# MCAN_CFG_52608000h register map
Vendor: Texas Instruments
Peripheral module from a debugger description file (folder AM263P).
Registers are 32-bit, read-write, reset 0x0 unless marked. A register's access mark holds for its fields unless they carry their own. Offsets are as the file gives them; lines under a group give offsets from that group; [hi:lo] are bit positions; {n}, {i} and the like mark numbered series; 'fields as' and 'values as' point back to an identical list; <NAME> marks a mode.

## CFG
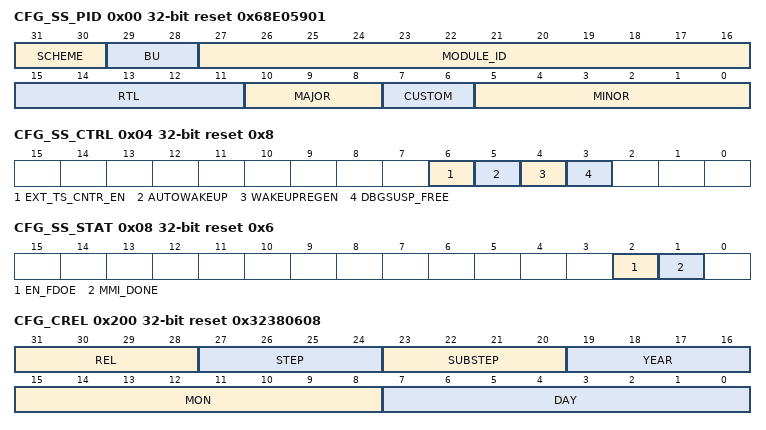
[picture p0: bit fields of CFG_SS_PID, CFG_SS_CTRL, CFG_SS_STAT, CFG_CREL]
0x00 CFG_SS_PID ro reset 0x68E05901 — Revision Register. The Revision Register contains the major and minor revisions for the MCANSS.
  [31:30] SCHEME — PID register scheme
  [29:28] BU — Business Unit: 10 = Processors
  [27:16] MODULE_ID
  [15:11] RTL — RTL revision. Will vary depending on release.
  [10:8] MAJOR — Major revision
  [7:6] CUSTOM
  [5:0] MINOR — Minor revision
0x04 CFG_SS_CTRL reset 0x8 — Control Register. The Control Register contains general control bits for the MCANSS.
  [6] EXT_TS_CNTR_EN — External TimeStamp Counter Enable
  [5] AUTOWAKEUP — Automatic Wakeup Enable
  [4] WAKEUPREGEN — Wakeup Request Enable
  [3] DBGSUSP_FREE — 0-Honor Debug Suspend, 1-Disregard debug suspend
0x08 CFG_SS_STAT ro reset 0x6 — Status Register. The Status Register provides general status bits for the MCANSS.
  [2] EN_FDOE — Enable FD configuration. Reflects the value of mcanss_enable_fdoe configuration port
  [1] MMI_DONE — 0:Memory Initialization is in progress, 1:Memory Intialization Done
0x0C CFG_SS_ICS wo — Interrupt Clear Shadow Register. Write 1 to clear interrupt bits.
  [0] ICS — This bit contains the External TimeStamp Counter Overflow Interrupt status. Write '1' to clear bits. [ICS - Interrupt Clear Shadow Register]
0x10 CFG_SS_IRS ro — Interrupt Raw Status Register. Write 1 to set interrupt bits.
  [0] IRS — External TimeStamp Counter Overflow Interrupt status. Read raw interrupt status. [IRS - Interrupt Raw Status Register]
0x14 CFG_SS_IECS wo — Interrupt Enable Clear Shadow Register. Write 1 to clear interrupt enable bits.
  [0] IECS — External TimeStamp Counter Overflow Interrupt. Write '1' to clear bits. [IECS - Interrupt Enable Clear Shadow Register]
0x18 CFG_SS_IE — Interrupt Enable Register. Write 1 to set interrupt bits.
  [0] IE — External TimeStamp Counter Overflow Interrupt. Write '1' to set interrupt enable. Read returns interrupt enable. [IE - Interrupt Enable Register]
0x1C CFG_SS_IES ro — Interrupt Enable Status Register. Read enabled interrupts.
  [0] IES — External TimeStamp Counter Overflow Interrupt. Read Enabled Interrupts. [IES - Interrupt Enable Status]
0x20 CFG_SS_EOI wo — End Of Interrupt (EOI) Register. The EOI register is used to re-trigger the pulse interrupt signal to ensure that any nested interrupt events are serviced. For level interrupt signals the EOI register is not functional and must not be used.
  [7:0] EOI — Write with bit position of targeted interrupt. [E.g. Ext TS is bit 0].Upon write, level interrupt will clear and if unserviced interrupt counter > 1 will issue another pulse interrupt. Field values: 8'h00: EOI value for External TS interrupt 8'h01: EOI value for mcan[0] interrupt 8'h02: EOI value for mcan[1] interruptAll other values are not applicable[EOI - End Of Interrupt]
0x24 CFG_SS_EXT_TS_PS — External Timestamp Prescaler Register.
  [23:0] PRESCALE — External Timestamp Prescaler reload value.External Timestamp count rate is host clock rate divided by this valuewith one exception: a value of 0 has the same effect as 1 .
0x28 CFG_SS_EXT_TS_USIC ro — External Timestamp Unserviced Interrupts Counter Register.
  [4:0] EXT_TS_INTR_CNTR — Number of unserviced rollover interrupts. If >1 an EOI write will issue another pulse interrupt [EXT_TS_USIC - External TImeStamp Unserviced Interrupts Counter]
0x200 CFG_CREL ro reset 0x32380608 — Core Release Register. Release dependent constant (version + date).
  [31:28] REL — Core Release
  [27:24] STEP — Step of Core Release
  [23:20] SUBSTEP — Sub-Step of Core Release
  [19:16] YEAR — Time Stamp Year
  [15:8] MON — Time Stamp Month
  [7:0] DAY — Time Stamp Day
0x204 CFG_ENDN ro reset 0x87654321 — Endian Register. Constant 8765 4321h.
  [31:0] ETV — Endianess test value
0x208 CFG_CUST ro — Custom Register.
  [31:0] CUST — Custom
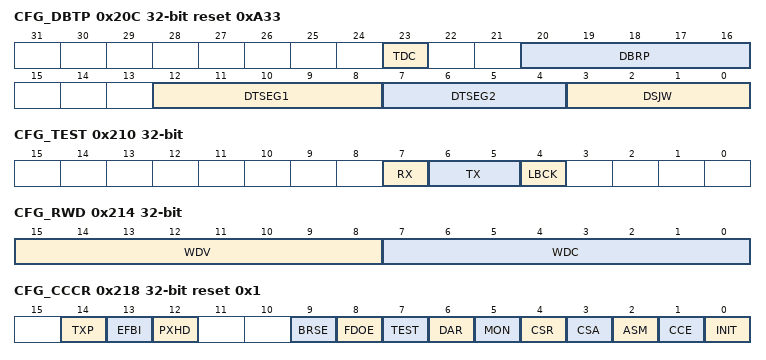
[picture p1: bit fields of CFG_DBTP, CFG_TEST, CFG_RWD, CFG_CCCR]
0x20C CFG_DBTP reset 0xA33 — Data Bit Timing & Prescaler Register. Configuration of data phase bit timing, transmitter delay compensation enable. This register is only writable if the MCAN_CCCR[1] CCE and MCAN_CCCR[0] INIT bits are set. The CAN bit time may be programed in the range of 4 to 49 time quanta. The CAN time quantum may be programmed in the range of 1 to 32 MCAN functional clock periods. tq = (MCAN_DBTP[20-16] DBRP + 1) mtq (minimum time quantum = CAN clock period (MCAN functional clock)). The MCAN_DBTP[12-8] DTSEG1 field is the sum of Prop_Seg and Phase_Seg1. The MCAN_DBTP[7-4] DTSEG2 field is Phase_Seg2. Therefore the length of the bit time is (programmed values) [MCAN_DBTP[12-8] DTSEG1 + MCAN_DBTP[7-4] DTSEG2 + 3] tq or (functional values) [Sync_Seg + Prop_Seg + Phase_Seg1 + Phase_Seg2] tq. The Information Processing Time (IPT) is zero, meaning the data for the next bit is available at the first clock edge after the sample point. Note: With a CAN clock (MCAN functional clock) of 8 MHz, the reset value of 0000 0A33h configures the MCAN module for a data phase bit rate of 500 kbit/s. Note: The bit rate configured for the CAN FD data phase via the MCAN_DBTP register must be higher or equal to the bit rate configured for the arbitration phase via the MCAN_DBTP register.
  [23] TDC — Transmitter Delay Compensation 1'b0 = Transmitter Delay Compensation disabled 1'b1 = Transmitter Delay Compensation enabled
  [20:16] DBRP — Data Baud Rate Prescaler The value by which the oscillator frequency is divided for generating the bit time quanta. The bit time is built up from a multiple of this quanta. The actual interpretation by the hardware of this value is such that one more than the value programmed here is used.
  [12:8] DTSEG1 — Data time segment before smaple point. The actual interpretation by the hardware of this value is such that one more than the value programmed here is used.
  [7:4] DTSEG2 — Data time segment after sample point. The actual interpretation by the hardware of this value is such that one more than the value programmed here is used.
  [3:0] DSJW — Data resynchronization Jump Width. The actual interpretation by the hardware of this value is such that one more than the value programmed here is used.
0x210 CFG_TEST access per field — Test Register. Test mode selection. Write access to the MCAN_TEST register has to be enabled by setting the MCAN_CCCR[7] TEST bit.
  [7] RX ro — Receive Pin Monitors the actual value of the MCAN RX pin 1'b0 = The CAN bus is dominant 1'b1 = The CAN bus is recessive
  [6:5] TX rw — Control of Transmit Pin 2'b00 = Reset value, the MCAN TX pin controlled by the CAN Core, updated at the end of the CAN bit time 2'b01 = Sample Point can be monitored at the MCAN TX pin 2'b10 = Dominant ('0') level at the MCAN TX pin 2'b11 = Recessive ('1') at the MCAN TX pin
  [4] LBCK rw — Loop Back Mode 1'b0 = Reset value, Loopback Mode is disabled 1'b1 = Loopback Mode is enabled(see Test Modes)
0x214 CFG_RWD access per field — RAM Watchdog. Monitors the READY output of the Message RAM.
  [15:8] WDV ro — Watchdog Value Actual Message RAM Watchdog Counter Value.
  [7:0] WDC rw — Watchdog Counter Value Start value of the Message RAM Watchdog Counter. With the reset value of 8'h0 the counter is disabled.
0x218 CFG_CCCR access per field reset 0x1 — CC Control Register. Operation mode configuration.
  [14] TXP rw — Transmit Pause If this bit is set, the MCAN module pauses for two CAN bit times before starting the next transmission after itself has successfully transmitted a frame(see Tx Handling) . 1'b0 = Transmit pause disabled 1'b1 = Transmit pause enabled
  [13] EFBI rw — Edge Filtering durign Bus Integration 1'b0 = Edge filtering disabled 1'b1 = Two consecutive dominant tq required to detect an edge for hard synchronization
  [12] PXHD rw — Protocol Exception Handling Disable 1'b0 = Protocol exception handling enabled 1'b1 = Protocol exception handling disabled Note: When protocol exception handling is disabled, the MCAN module will transmit an error frame when it detects a protocol exception condition.
  [9] BRSE rw — Bit Rate Switch Enable 1'b0 = Bit rate switching for transmissions disabled 1'b1 = Bit rate switching for transmissions enabled Note: When CAN FD operation is disabled the MCAN_CCCR[8] FDOE = 1'b0, the MCAN_CCCR[9] BRSE bit is not evaluated.
  [8] FDOE rw — FD Operation Enable 1'b0 = FD operation disabled 1'b1 = FD operation enabled
  [7] TEST rw — Test Mode enable 1'b0 = Normal operation. The MCAN_TEST register holds reset values. 1'b1 = Test Mode. Write access to the MCAN_TEST register enabled
  [6] DAR rw — Disable Automatic Regransmission 1'b0 = Automatic retransmission of messages not transmitted successfully enabled 1'b1 = Automatic retransmission disabled
  [5] MON rw — Bus Monitoring Mode The MCAN_CCCR[5] MON bit can only be set by the Host CPU when both MCAN_CCCR[1] CCE and MCAN_CCCR[0] INIT bits are set to 1. The bit can be reset by the Host CPU at any time. 1'b0 = Bus Monitoring Mode is disabled 1'b1 = Bus Monitoring Mode is enabled
  [4] CSR rw — Clock Stop Request 1'b0 = No clock stop is requested 1'b1 = Clock stop requested. When clock stop is requested, first the MCAN_CCCR[0] INIT bit and then the MCAN_CCCR[3] CSA bit will be set after all pending transfer requests have been completed and the CAN bus reached idle.
  [3] CSA ro — Clock Stop Acknowledge 1'b0 = No clock stop acknowledged 1'b1 = The MCAN module may be set in power down by stopping MCAN interface clock and MCAN functional clock
  [2] ASM rw — Restriced Operation Mode The MCAN_CCCR[2] ASM bit can only be set by the Host CPU when both MCAN_CCCR[1] CCE and MCAN_CCCR[0] INIT bits are set to 1. The bit can be reset by the Host CPU at any time. For a description of the Restricted Operation Mode, see Restricted Operation Mode. 1'b0 = Normal CAN operation 1'b1 = Restricted Operation Mode active
  [1] CCE rw — Configuration Change Enable 1'b0 = The Host CPU has no write access to the protected configuration registers 1'b1 = The Host CPU has write access to the protected configuration registers (while the MCAN_CCCR[0] INIT = 1)
  [0] INIT rw — Initialization 1'b0 = Normal Operation 1'b1 = Initialization is started Note: Due to the synchronization mechanism between the two clock domains, there may be a delay until the value written to the MCAN_CCCR[0] INIT bit can be read back. Therefore the software has to assure that the previous value written to the MCAN_CCCR[0] INIT bit has been accepted by Reading the MCAN_CCCR[0] INIT bit before setting the MCAN_CCCR[0] INIT bit to a new value.
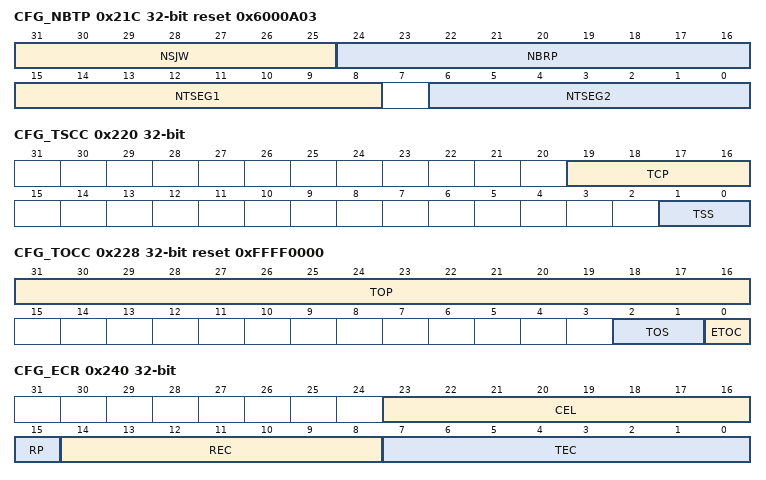
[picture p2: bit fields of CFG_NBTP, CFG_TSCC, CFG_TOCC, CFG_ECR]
0x21C CFG_NBTP reset 0x6000A03 — Nominal Bit Timing & Prescaler Register. Configuration of arbitration phase bit timing. This register is only writable if the MCAN_CCCR[1] CCE and MCAN_CCCR[0] INIT bits are set. The CAN bit time may be programed in the range of 4 to 385 time quanta. The CAN time quantum may be programmed in the range of 1 to 512 MCAN functional clock periods. tq = (MCAN_NBTP[24-16] NBRP + 1) mtq. The MCAN_NBTP[15-8] NTSEG1 field is the sum of Prop_Seg and Phase_Seg1. The MCAN_NBTP[6-0] NTSEG2 field is Phase_Seg2. Therefore the length of the bit time is (programmed values) [MCAN_NBTP[15-8] NTSEG1 + MCAN_NBTP[6-0] NTSEG2 + 3] tq or (functional values) [Sync_Seg + Prop_Seg + Phase_Seg1 + Phase_Seg2] tq. The Information Processing Time (IPT) is zero, meaning the data for the next bit is available at the first clock edge after the sample point.
  [31:25] NSJW — Nominal Resynchronization Jump Width
  [24:16] NBRP — Nominal Baud Rate Prescaler
  [15:8] NTSEG1 — Nominal Time segment before sample point
  [6:0] NTSEG2 — Nominal Time segment after sample point
0x220 CFG_TSCC — Timestamp Counter Configuration. Timestamp counter prescaler setting, selection of internal/external timestamp vector.
  [19:16] TCP — Timestamp Counter Prescaler Configures the timestamp and timeout counters time unit in multiples of CAN bit times [1-16]. The actual interpretation by the hardware of this value is such that one more than the value programmed here is used. Note: With CAN FD an external counter is required for timestamp generation. MCAN_TSCC[1-0] TSS = 2'b10
  [1:0] TSS — Timestamp Select 2'b00 = Timestamp counter value always 0 2'b01 = Timestamp counter value incremented according to the MCAN_TSCC[19-16] TCP field 2'b10 = External timestamp counter value used 2'b11 = Same as 2'b00
0x224 CFG_TSCV — Timestamp Counter Value.
  [15:0] TSC — Timestamp Counter The internal/external Timestamp Counter value is captured on start of frame (both Rx and Tx). When the MCAN_TSCC[1-0] TSS = 2'b01, the Timestamp Counter is incremented in multiples of CAN bit times [1-16] depending on the configuration of the MCAN_TSCC[19-16] TCP field. A wrap around sets interrupt flag MCAN_IR[16] TSW. Write access resets the counter to zero. When the MCAN_TSCC[1-0] TSS = 2'b10, the MCAN_TSCV[15-0] TSC field reflects the external Timestamp Counter value. A write access has no impact. Note: A 'wrap around' is a change of the Timestamp Counter value from non-zero to zero not caused by write access to the MCAN_TSCV register.
0x228 CFG_TOCC reset 0xFFFF0000 — Timeout Counter Configuration Configuration of timeout period, selection of timeout counter operation mode.
  [31:16] TOP — Timeout Period Start value of the Timeout Counter (down-counter). Configures the Timeout Period.
  [2:1] TOS — Timeout Select When operating in Continuous mode, a write to the MCAN_TOCV[15-0] TOC field presets the counter to the value configured by the MCAN_TOCC[31-16] TOP field and continues down-counting. When the Timeout Counter is controlled by one of the FIFOs, an empty FIFO presets the counter to the value configured by the MCAN_TOCC[31-16] TOP field. Down-counting is started when the first FIFO element is stored. 2'b00 = Continuous operation 2'b01 = Timeout controlled by Tx Event FIFO 2'b10 = Timeout controlled by Rx FIFO 0 2'b11 = Timeout controlled by Rx FIFO 1
  [0] ETOC — Enable Timeout Counter 1'b0 = Timeout Counter disabled 1'b1 = Timeout Counter enabled
0x22C CFG_TOCV reset 0xFFFF — Timeout Counter Value. Read/reset timeout counter.
  [15:0] TOC — Timeout Counter The Timeout Counter is decremented in multiples of CAN bit times [1-16] depending on the configuration of the MCAN_TSCC[19-16] TCP field. When decremented to zero, interrupt flag MCAN_IR[18] TOO is set and the Timeout Counter is stopped. Start and reset/restart conditions are configured via the MCAN_TOCC[2-1] TOS field.
0x240 CFG_ECR ro — Error Counter Register. State of Rx/Tx Error counter, CAN error logging.
  [23:16] CEL — CAN Error Logging The counter is incremented each time when a CAN protocol error causes the Transmit Error Counter or the Receive Error Counter to be incremented. It is reset by read access to the MCAN_ECR[23-16] CEL field. The counter stops at FFh; the next increment of the MCAN_ECR[7-0] TEC or MCAN_ECR[14-8] REC fields sets interrupt flag MCAN_IR[22] ELO.
  [15] RP — Recieve Error Passive 1'b0 = The Receive Error Counter is below the error passive level of 128 1'b1 = The Receive Error Counter has reached the error passive level of 128
  [14:8] REC — Recieve Error Counter Actual state of the Receive Error Counter, values between 0 and 127.
  [7:0] TEC — Transmit Error Counter Actual state of the Transmit Error Counter, values between 0 and 255. Note: When the MCAN_CCCR[2] ASM bit is set, the CAN protocol controller does not increment the MCAN_ECR[7-0] TEC and MCAN_ECR[14-8] REC fields when a CAN protocol error is detected, but the MCAN_ECR[23-16] CEL field is still incremented.
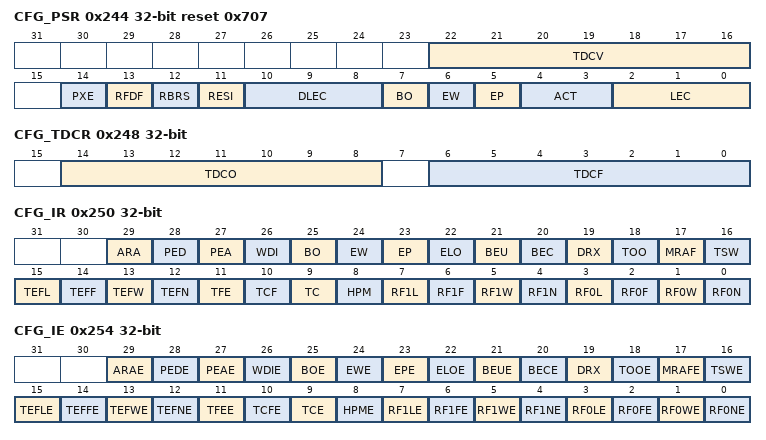
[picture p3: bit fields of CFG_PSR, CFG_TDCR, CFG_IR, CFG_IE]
0x244 CFG_PSR ro reset 0x707 — Protocol Status Register. CAN protocol controller status, transmitter delay compensation value.
  [22:16] TDCV — Transmitter Delay Compensation Value Position of the secondary sample point, defined by the sum of the measured delay from the MCAN TX to MCAN RX pins and the MCAN_TDCR[14-8] TDCO field. The SSP position is, in the data phase, the number of mtq between the start of the transmitted bit and the secondary sample point. Valid values are 0 to 127 mtq.
  [14] PXE — Protocol Exception Event 1'b0 = No protocol exception event occurred since last read access 1'b1 = Protocol exception event occurred
  [13] RFDF — Recieved a CAN FD Message This bit is set independent of acceptance filtering. 1'b0 = Since this bit was reset by the Host CPU, no CAN FD message has been received 1'b1 = Message in CAN FD format with FDF flag set has been received
  [12] RBRS — BRS flag of last recieved CAN FD Message This bit is set together with the MCAN_PSR[13] RFDF bit, independent of acceptance filtering. 1'b0 = Last received CAN FD message did not have its BRS flag set 1'b1 = Last received CAN FD message had its BRS flag set
  [11] RESI — ESI flag of last recieved CAN FD Message This bit is set together with the MCAN_PSR[13] RFDF bit, independent of acceptance filtering. 1'b0 = Last received CAN FD message did not have its ESI flag set 1'b1 = Last received CAN FD message had its ESI flag set
  [10:8] DLEC — Data Phase Last Error Code Type of last error that occurred in the data phase of a CAN FD format frame with its BRS flag set. Coding is the same as for the MCAN_PSR[2-0] LEC field. This field will be cleared to zero when a CAN FD format frame with its BRS flag set has been transferred (reception or transmission) without error.
  [7] BO — Bus_Off status 1'b0 = The MCAN module is not Bus_Off 1'b1 = The MCAN module is in Bus_Off state
  [6] EW — Warning Status 1'b0 = Both error counters are below the Error_Warning limit of 96 1'b1 = At least one of error counter has reached the Error_Warning limit of 96
  [5] EP — Error Passive 1'b0 = The MCAN module is in the Error_Active state. It normally takes part in bus communication and sends an active error flag when an error has been detected 1'b1 = The MCAN module is in the Error_Passive state
  [4:3] ACT — Activity Monitors the module's CAN communication state. 2'b00 = Synchronizing - node is synchronizing on CAN communication 2'b01 = Idle - node is neither receiver nor transmitter 2'b10 = Receiver - node is operating as receiver 2'b11 = Transmitter - node is operating as transmitter Note: ACT is set to 0 by a Protocol Exception Event.
  [2:0] LEC — Last Error Code The MCAN_PSR[2-0] LEC field indicates the type of the last error to occur on the CAN bus. This field will be cleared to0hwhen a message has been transferred (reception or transmission) without error. 3'b000 = No Error: No error occurred since the MCAN_PSR[2-0] LEC field has been reset by successful reception or transmission. 3'b001 = Stuff Error: More than 5 equal bits in a sequence have occurred in a part of a received message where this is not allowed. 3'b010 = Form Error: A fixed format part of a received frame has the wrong format. 3'b011 = AckError: The message transmitted by the MCAN module was not acknowledged by another node. 3'b100 = Bit1Error: During the transmission of a message (with the exception of the arbitration field), the device wanted to send a recessive level (bit of logical value '1'), but the monitored bus value was dominant. 3'b101 = Bit0Error: During the transmission of a message (or acknowledge bit, or active error flag, or overload flag), the device wanted to send a dominant level (data or identifier bit logical value 0), but the monitored bus value was recessive. During Bus_Off recovery this status is set each time a sequence of 11 recessive bits has been monitored. This enables the Host CPU to monitor the proceeding of the Bus_Off recovery sequence (indicating the bus is not stuck at dominant or continuously disturbed). 3'b110 = CRCError: The CRC check sum of a received message was incorrect. The CRC of an incom-ing message does not match with the CRC calculated from the received data. 3'b111 = NoChange: Any read access to the Protocol Status Register re-initializes the MCAN_PSR[2-0] LEC field to 3'b111. When the MCAN_PSR[2-0] LEC field shows the value 3'b111, no CAN bus event was detected since the last Host CPU read access to the Protocol Status Register. Note: When a frame in CAN FD format has reached the data phase with BRS flag set, the next CAN event (error or valid frame) will be shown in the MCAN_PSR[10-8] DLEC field instead of the MCAN_PSR[2-0] LEC field. An error in a fixed stuff bit of a CAN FD CRC sequence will be shown as a Form Error, not Stuff Error.
0x248 CFG_TDCR — Transmitter Delay Comensation Register. Configuration of transmitter delay compensation offset and filter window length.
  [14:8] TDCO — Transmitter Delay Compensation Offset Offset value defining the distance between the measured delay from the MCAN RX and MCAN TX pins and the secondary sample point. Valid values are 0 to 127 mtq 0h7Fh).
  [6:0] TDCF — Transmitter Delay Compensation Filter Window Length Defines the minimum value for the SSP position, dominant edges on the MCAN RX pin that would result in an earlier SSP position are ignored for transmitter delay measure-ment. The feature is enabled when the MCAN_TDCR[6-0] TDCF field is configured to a value greater than the MCAN_TDCR[14-8] TDCO field. Valid values are 0 to 127 mtq
0x250 CFG_IR — Interrupt Register. The flags are set when one of the listed conditions is detected (edge-sensitive). The flags remain set until the Host CPU clears them. A flag is cleared by writing a 1h to the corresponding bit position. Writing a 0h has no effect.
  [29] ARA — Access to Reserved Address
  [28] PED — Protocol Error in data Phase
  [27] PEA — Protocol Error in Arbitration Phase
  [26] WDI — Watchdog Interrupt
  [25] BO — Bus_Off Status
  [24] EW — Warning Status
  [23] EP — Error Passive
  [22] ELO — Error Logging Overflow
  [21] BEU — Bit Error Uncorrected
  [20] BEC — Bit Error Corrected
  [19] DRX — Message stored to Dedicated Rx Buffer
  [18] TOO — Timeout Occurred
  [17] MRAF — Message RAM Access Failure The flag is set, when the Rx Handler: i. has not completed acceptance filtering or storage of an accepted message until the arbitration field of the following message has been received. In this case acceptance filtering or message storage is aborted and the Rx Handler starts processing of the following message. ii. was not able to write a message to the Message RAM. In this case message storage is aborted. In both cases the FIFO put index is not updated respectively the New Data flag for a dedicated Rx Buffer is not set, a partly stored message is overwritten when the next message is stored to this location. The flag is also set when the Tx Handler was not able to read a message from the Message RAM in time. In this case message transmission is aborted. In case of a Tx Handler access failure the MCAN module is switched into Restricted Operation Mode (see Restricted Operation Mode). To leave Restricted Operation Mode, the Host CPU has to reset the MCAN_CCCR[2] ASM bit. 1'b0 = No Message RAM access failure occurred 1'b1 = Message RAM access failure occurred
  [16] TSW — Timestamp Wraparound
  [15] TEFL — Tx Event FIFO Element Lost
  [14] TEFF — Tx Event FIFO Full
  [13] TEFW — Tx Event FIFO Watermark Reached
  [12] TEFN — Tx Event FIFO New Entry
  [11] TFE — Tx FIFO Empty
  [10] TCF — Transmission Cancellation Finished
  [9] TC — Transmission Complete
  [8] HPM — High Priority Message
  [7] RF1L — Rx FIFO 1 Message Lost
  [6] RF1F — Rx FIFO 1 Full
  [5] RF1W — Rx FIFO 1 Watermark Reached
  [4] RF1N — Rx FIFO 1 New Message
  [3] RF0L — Rx FIFO 0 Message Lost
  [2] RF0F — Rx FIFO 0 Full
  [1] RF0W — Rx FIFO 0 Watermark Reached
  [0] RF0N — Rx FIFO 0 New Message
0x254 CFG_IE — Interrupt Enable Register. The settings in the Interrupt Enable register determine which status changes in the MCAN_IR register are signalled on an interrupt line.
  [29] ARAE — Accees to Reserve Address Interrupt Enable
  [28] PEDE — Protocol Error in Data Phase Interrupt Enable
  [27] PEAE — Protocol Error in Arbitration Phase Interrupt Enable
  [26] WDIE — Watchdog Interrupt Enable
  [25] BOE — Bus_Off Status Interrupt Enable
  [24] EWE — Warning Status Interrupt Enable
  [23] EPE — Error Passive Interrupt Enable
  [22] ELOE — Error Logging Overflow Interrupt Enable
  [21] BEUE — Bit Error Uncorrected Interrupt Enable
  [20] BECE — Bit Error Corrected Interrupt Enable
  [19] DRX — Message stored to Dedicated Rx Buffer Interrupt Enable
  [18] TOOE — Timeout Occurred Interrupt Enable
  [17] MRAFE — Message RAM Access Failure Interrupt Enable
  [16] TSWE — Timestamp Wraparound Interrupt Enable
  [15] TEFLE — Tx Event FIFO Event Lost Interrupt Enable
  [14] TEFFE — Tx Event FIFO Full Interrupt Enable
  [13] TEFWE — Tx Event FIFO Watermark Reached Interrupt enable
  [12] TEFNE — Tx Event FIFO New Entry Interrupt Enable
  [11] TFEE — Tx FIFO Empty Interrupt Enable
  [10] TCFE — Transmission Cancellation Finishied Interrupt Enable
  [9] TCE — Transmission Completed Interrupt Enable
  [8] HPME — High Priority message Interrupt Enable
  [7] RF1LE — Rx FIFO 1 Message Lost Interrupt Enable
  [6] RF1FE — Rx FIFO 1 Full Interrupt Enable
  [5] RF1WE — Rx FIFO 1 Watermark Reached Interrupt Enable
  [4] RF1NE — Rx FIFO 1 New Message Interrupt Enable
  [3] RF0LE — Rx FIFO 0 Message Lost Interrupt Enable
  [2] RF0FE — Rx FIFO 0 Full Interrupt Enable
  [1] RF0WE — Rx FIFO 0 Watermark Reached Interrupt Enable
  [0] RF0NE — Rx FIFO 0 New Message Interrupt Enable
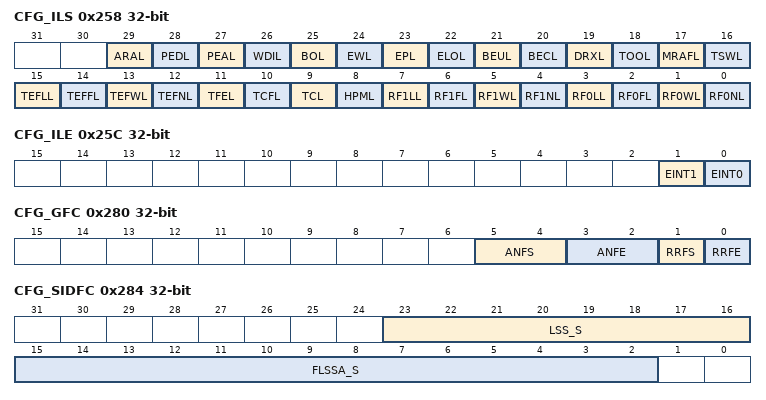
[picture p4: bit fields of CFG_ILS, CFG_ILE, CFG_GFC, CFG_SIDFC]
0x258 CFG_ILS — Interrupt line select. The Interrupt Line Select register assigns an interrupt generated by a specific interrupt flag from the MCAN_IR register to one of the two module interrupt lines. For assigning interrupt to INT0, write 0 to corresponding bit field and for assigning interrupt to INT1, write 1 to corresponding bit field.
  [29] ARAL — Accees to Reserve Address Interrupt Line
  [28] PEDL — Protocol Error in Data Phase Interrupt Line
  [27] PEAL — Protocol Error in Arbitration Phase Interrupt Line
  [26] WDIL — Watchdog Interrupt Line
  [25] BOL — Bus_Off Status Interrupt Line
  [24] EWL — Warning Status Interrupt Line
  [23] EPL — Error Passive Interrupt Line
  [22] ELOL — Error Logging Overflow Interrupt Line
  [21] BEUL — Bit Error Uncorrected Interrupt Line
  [20] BECL — Bit Error Corrected Interrupt Line
  [19] DRXL — Message stored to Dedicated Rx Buffer Interrupt Line
  [18] TOOL — Timeout Occurred Interrupt Line
  [17] MRAFL — Message RAM Access Failure Interrupt Line
  [16] TSWL — Timestamp Wraparound Interrupt Line
  [15] TEFLL — Tx Event FIFO Event Lost Interrupt Line
  [14] TEFFL — Tx Event FIFO Full Interrupt Line
  [13] TEFWL — Tx Event FIFO Watermark Reached Interrupt Line
  [12] TEFNL — Tx Event FIFO New Entry Interrupt Line
  [11] TFEL — Tx FIFO Empty Interrupt Line
  [10] TCFL — Transmission Cancellation Finishied Interrupt Line
  [9] TCL — Transmission Completed Interrupt Line
  [8] HPML — High Priority message Interrupt Line
  [7] RF1LL — Rx FIFO 1 Message Lost Interrupt Line
  [6] RF1FL — Rx FIFO 1 Full Interrupt Line
  [5] RF1WL — Rx FIFO 1 Watermark Reached Interrupt Line
  [4] RF1NL — Rx FIFO 1 New Message Interrupt Line
  [3] RF0LL — Rx FIFO 0 Message Lost Interrupt Line
  [2] RF0FL — Rx FIFO 0 Full Interrupt Line
  [1] RF0WL — Rx FIFO 0 Watermark Reached Interrupt Line
  [0] RF0NL — Rx FIFO 0 New Message Interrupt Line
0x25C CFG_ILE — Interrupt line enable Register. Enable/Disable interrupt lines INT0/INT1.
  [1] EINT1 — Enable Interrupt Line 1
  [0] EINT0 — Enable Interrupt Line 0
0x280 CFG_GFC — Global Filter Configuration. Handling of non-matching frames and remote frames. Global settings for Message ID filtering. The MCAN_GFC register controls the filter path for standard and extended messages.
  [5:4] ANFS — Accept Non-matching Frames Standard Defines how received messages with 11-bit IDs that do not match any element of the filter list are treated. 2'b00 = Accept in Rx FIFO 0 2'b01 = Accept in Rx FIFO 1 2'b10 = Reject 2'b11 = Reject
  [3:2] ANFE — Accept Non-matching Frames Extended Defines how received messages with 29-bit IDs that do not match any element of the filter list are treated. 2'b00 = Accept in Rx FIFO 0 2'b01 = Accept in Rx FIFO 1 2'b10 = Reject 2'b11 = Reject
  [1] RRFS — Reject Remote Frames Standard 1'b0 = Filter remote frames with 11-bit standard IDs 1'b1 = Reject all remote frames with 11-bit standard IDs
  [0] RRFE — Reject Remote Frames Extended 1'b0 = Filter remote frames with 29-bit extended IDs 1'b1 = Reject all remote frames with 29-bit extended IDs
0x284 CFG_SIDFC — Standard ID Filter Configuration. Settings for 11-bit standard Message ID filtering. The Standard ID Filter Configuration controls the filter path for standard messages.
  [23:16] LSS_S — List Size Standard 8'h00 = No standard Message ID filter 8'h01-8'h80 (1-128) = Number of standard Message ID filter elements > 8'h80 (128) = Values greater than 128 are interpreted as 128
  [15:2] FLSSA_S — Filter List Standard Start Address Start address of standard Message ID filter list (32-bit word address, see Message RAM Configuration).
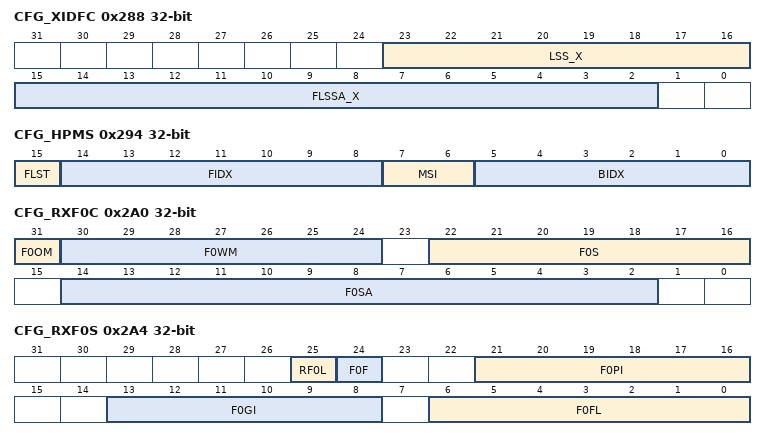
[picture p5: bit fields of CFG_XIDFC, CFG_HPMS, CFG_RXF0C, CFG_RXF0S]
0x288 CFG_XIDFC — Extended ID Filter Configuration. Settings for 29-bit extended Message ID filtering. The Extended ID Filter Configuration controls the filter path for standard messages.
  [23:16] LSS_X — List Size Extended 8'h00 = No extended Message ID filter 8'h01-8'h40 (1-64) = Number of extended Message ID filter elements > 8'h40 (64) = Values greater than 64 are interpreted as 64
  [15:2] FLSSA_X — Filter List Extended Start Address Start address of extended Message ID filter list (32-bit word address, see Message RAM Configuration).
0x290 CFG_XIDAM reset 0x1FFFFFFF — Extended ID and Mask.
  [28:0] EIDM — Extended ID Mask. For acceptance filtering of extended frames the Extended ID AND Mask is ANDed with the Message ID of a received frame. Intended for masking of 29-bit IDs in SAE J1939. With the reset value of all bits set to one the mask is not active.
0x294 CFG_HPMS ro — High Priority Message Status. Status monitoring of incoming high priority messages. This register is updated every time a Message ID filter element configured to generate a priority event matches. This can be used to monitor the status of incoming high priority messages and to enable fast access to these messages.
  [15] FLST — Filter List Indicates the filter list of the matching filter element. 1'b0 = Standard Filter List 1'b1 = Extended Filter List
  [14:8] FIDX — Filter Index Index of matching filter element. Range is 0 to MCAN_SIDFC[23-16] LSS - 1 respectively MCAN_XIDFC[22-16] LSE - 1.
  [7:6] MSI — Message Storeage Indicator 2'b00 = No FIFO selected 2'b01 = FIFO message lost 2'b10 = Message stored in FIFO 0 2'b11 = Message stored in FIFO 1
  [5:0] BIDX — Buffer Index Index of Rx FIFO element to which the message was stored. Only valid when the MCAN_HPMS[7-6] MSI = 1.
0x298 CFG_NDAT1 — New Data 1 register. NewData flags of dedicated Rx buffers 0-31. The register holds the New Data flags of Rx Buffers 0 to 31. The flags are set when the respective Rx Buffer has been updated from a received frame. The flags remain set until the Host CPU clears them. Aflag is cleared by writing a 1h to the corresponding bit position. Writing a 0h has no effect. A hard reset will clear the register .
  [31:0] ND0_31 — New Data 31-0
0x29C CFG_NDAT2 — New Data 2 register. NewData flags of dedicated Rx buffers 32-63. The register holds the New Data flags of Rx Buffers 32 to 63. The flags are set when the respective Rx Buffer has been updated from a received frame. The flags remain set until the Host CPU clears them. A flag is cleared by writing a 1h to the corresponding bit position. Writing a 0h has no effect. A hard reset will clear the register .
  [31:0] ND32_63 — New Data 63-32
0x2A0 CFG_RXF0C — Rx FIFO 0 Configuration register. FIFO 0 operation mode, watermark, size and start address.
  [31] F0OM — Rx FIFO 0 Operation Mode FIFO 0 can be operated in blocking or in overwrite mode (see Rx FIFOs). 1'b0 = FIFO 0 blocking mode 1'b1 = FIFO 0 overwrite mode
  [30:24] F0WM — Rx FIFO 0 Watermark 7'h00 = Watermark interrupt disabled 7'h01-7'h40 (1-64) = Level for Rx FIFO 0 watermark interrupt (MCAN_IR[1] RF0W) > 7'h40 (64) = Watermark interrupt disabled
  [22:16] F0S — Rx FIFO 0 Size 7'h00 = No Rx FIFO 0 7'h01-7'h40 (1-64) = Number of Rx FIFO 0 elements > 7'h40 (64) = Values greater than 64 are interpreted as 64 The Rx FIFO 0 elements are indexed from 0 to MCAN_RXF0C[22-16] F0S - 1.
  [14:2] F0SA — Rx FIFO 0 Start Address Start address of Rx FIFO 0 in Message RAM (32-bit word address, see Message RAM Configuration).
0x2A4 CFG_RXF0S ro — Rx FIFO 0 Status register. FIFO 0 message lost/full indication, put index, get index and fill level.
  [25] RF0L — Rx FIFO 0 Message Lost This bit is a copy of interrupt flag MCAN_IR[3] RF0L. When the MCAN_IR[3] RF0L flag is reset, this bit is also reset. 1'b0 = No Rx FIFO 0 message lost 1'b1 = Rx FIFO 0 message lost, also set after write attempt to Rx FIFO 0 of size zero Note: OverWriting the oldest message when the MCAN_RXF0C[31] F0OM = 1'b1 will not set this flag.
  [24] F0F — Rx FIFO 0 Full
  [21:16] F0PI — Rx FIFO 0 Put Index
  [13:8] F0GI — Rx FIFO 0 Get Index
  [6:0] F0FL — Rx FIFO 0 Fill Level
0x2A8 CFG_RXF0A — Rx FIFO 0 Acknowledge register. FIFO 0 acknowledge last index of read buffers, updates get index and fill level.
  [5:0] F0AI — Rx FIFO 0 Acknowledge Index After the Host CPU has read a message or a sequence of messages from Rx FIFO 0 it has to write the buffer index of the last element read from Rx FIFO 0 to the MCAN_RXF0A[5-0] F0AI field. This will set the Rx FIFO 0 Get Index MCAN_RXF0S[13-8] F0GI field to the MCAN_RXF0A[5-0] F0AI field + 1 and update the FIFO 0 Fill Level MCAN_RXF0S[6-0] F0FL field.
0x2AC CFG_RXBC — Rx Buffer Configuration register. Start address of Rx buffer section.
  [15:2] RBSA — Rx Buffer Start Address
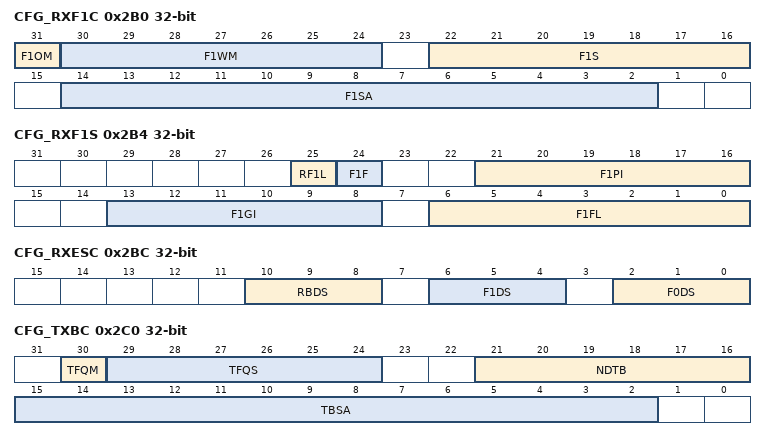
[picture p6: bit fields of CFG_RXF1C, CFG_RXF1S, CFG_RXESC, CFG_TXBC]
0x2B0 CFG_RXF1C — Rx FIFO 1 Configuration register. FIFO 1 operation mode, watermark, size and start address.
  [31] F1OM — Rx FIFO 1 Operation Mode FIFO 1 can be operated in blocking or in overwrite mode (see Rx FIFOs). 1'b0 = FIFO 1 blocking mode 1'b1 = FIFO 1 overwrite mode
  [30:24] F1WM — Rx FIFO 1 Watermark 7'h00 = Watermark interrupt disabled 7'h01-7'h40 (1-64) = Level for Rx FIFO 1 watermark interrupt (MCAN_IR[5] RF1W) > 7'h40 (64) = Watermark interrupt disabled
  [22:16] F1S — Rx FIFO 1 Size 7'h00 = No Rx FIFO 1 7'h01-7'h40 (1-64) = Number of Rx FIFO 1 elements > 7'h40 (64) = Values greater than 64 are interpreted as 64 The Rx FIFO 1 elements are indexed from 0 to MCAN_RXF1C[22-16] F1S - 1.
  [14:2] F1SA — Rx FIFO 1 Start Address Start address of Rx FIFO 1 in Message RAM (32-bit word address, see Message RAM Configuration).
0x2B4 CFG_RXF1S ro — Rx FIFO 1 Status register. FIFO 1 message lost/full indication, put index, get index and fill level.
  [25] RF1L — Rx FIFO 1 Message Lost This bit is a copy of interrupt flag MCAN_IR[7] RF1L. When the MCAN_IR[7] RF1L flag is reset, this bit is also reset. 1'b0 = No Rx FIFO 1 message lost 1'b1 = Rx FIFO 1 message lost, also set after write attempt to Rx FIFO 1 of size zero Note: OverWriting the oldest message when the MCAN_RXF1C[31] F1OM = 1'b1 will not set this flag.
  [24] F1F — Rx FIFO 1 Full
  [21:16] F1PI — Rx FIFO 1 Put Index
  [13:8] F1GI — Rx FIFO 1 Get Index
  [6:0] F1FL — Rx FIFO 1 Fill Level
0x2B8 CFG_RXF1A — Rx FIFO 1 Acknowledge register. FIFO 1 acknowledge last index of read buffers, updates get index and fill level.
  [5:0] F1AI — Rx FIFO 1 Acknowledge Index After the Host CPU has read a message or a sequence of messages from Rx FIFO 1 it has to write the buffer index of the last element read from Rx FIFO 1 to the MCAN_RXF1A[5-0] F1AI field. This will set the Rx FIFO 1 Get Index MCAN_RXF1S[13-8] F1GI field to the MCAN_RXF1A[5-0] F1AI field + 1 and update the FIFO 1 Fill Level MCAN_RXF1S[6-0] F1FL field.
0x2BC CFG_RXESC — Rx Buffer/FIFO Element Size Configuration register. Configure data field size for storage of accepted frames.
  [10:8] RBDS — Rx Buffer data Field Size 3'b000 = 8 byte data field 3'b001 = 12 byte data field 3'b010 = 16 byte data field 3'b011 = 20 byte data field 3'b100 = 24 byte data field 3'b101 = 32 byte data field 3'b110 = 48 byte data field 3'b111 = 64 byte data field
  [6:4] F1DS — Rx FIFO 1 Data Field Size 3'b000 = 8 byte data field 3'b001 = 12 byte data field 3'b010 = 16 byte data field 3'b011 = 20 byte data field 3'b100 = 24 byte data field 3'b101 = 32 byte data field 3'b110 = 48 byte data field 3'b111 = 64 byte data field
  [2:0] F0DS — Rx FIFO 0 Data Field Size 3'b000 = 8 byte data field 3'b001 = 12 byte data field 3'b010 = 16 byte data field 3'b011 = 20 byte data field 3'b100 = 24 byte data field 3'b101 = 32 byte data field 3'b110 = 48 byte data field 3'b111 = 64 byte data field Note: In case the data field size of an accepted CAN frame exceeds the data field size configured for the matching Rx Buffer or Rx FIFO, only the number of bytes as configured by the MCAN_RXESC register are stored to the Rx Buffer respectively Rx FIFO element. The rest of the frame's data field is ignored.
0x2C0 CFG_TXBC ro — Tx Buffer Configuration register. Configure Tx FIFO/Queue mode, Tx FIFO/Queue size, number of dedicated Tx buffers, Tx buffer start address.
  [30] TFQM — Tx FIFO/Queue Mode 1'b0 = Tx FIFO operation 1'b1 = Tx Queue operation
  [29:24] TFQS — Transmit FIFO/Queue Size 6'h00 = No Tx FIFO/Queue 6'b01-6'h20 (1-32) = Number of Tx Buffers used for Tx FIFO/Queue > 6'h20 (32) = Values greater than 32 are interpreted as 32
  [21:16] NDTB — Number of Dedicated Transmit Buffers 6'h00 = No Dedicated Tx Buffers 6'h01-6'h20 (1-32) = Number of Dedicated Tx Buffers > 6'h20 (32) = Values greater than 32 are interpreted as 32
  [15:2] TBSA — Tx Buffers Start Address Start address of Tx Buffers section in Message RAM (32-bit word address, see Message RAM Configuration). Note: Be aware that the sum of the MCAN_TXBC[29-24] TFQS and MCAN_TXBC[21-16] NDTB fields may be not greater than 32. There is no check for erroneous configurations. The Tx Buffers section in the Message RAM starts with the dedicated Tx Buffers.
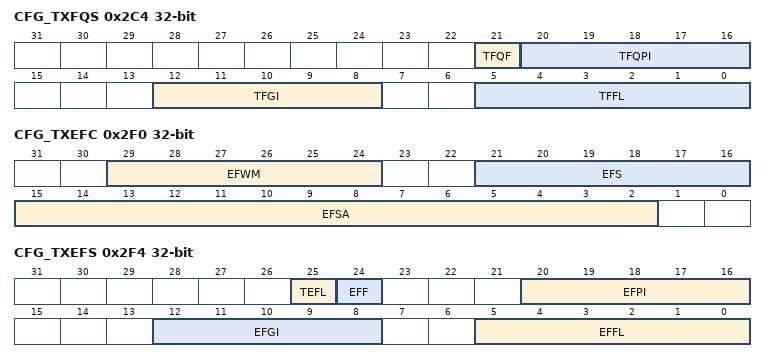
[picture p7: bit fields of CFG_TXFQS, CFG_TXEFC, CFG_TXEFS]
0x2C4 CFG_TXFQS ro — Tx FIFO/Queue Status register. Tx FIFO/Queue full indication and put index, Tx FIFO get index and fill level. The Tx FIFO/Queue status is related to the pending Tx requests listed in the MCAN_TXBRP register. Therefore the effect of Add/Cancellation requests may be delayed due to a running Tx scan (the MCAN_TXBRP register not yet updated).
  [21] TFQF — Tx FIFO/Queue Full
  [20:16] TFQPI — Tx FIFO/Queue Put Index
  [12:8] TFGI — Tx Queue Get Index
  [5:0] TFFL — Tx FIFO Free Level. Number of consecutive free Tx FIFO elements starting from the MCAN_TXFQS[12-8] TFGI field, range 0 to 32. Read as zero when Tx Queue operation is configured (MCAN_TXBC[30] TFQM = 1'b1). Note: In case of mixed configurations where dedicated Tx Buffers are combined with a Tx FIFO or a Tx Queue, the Put and Get Indices indicate the number of the Tx Buffer starting with the first dedicated Tx Buffers.
0x2C8 CFG_TXESC — Tx Buffer Element Size Configuration register. ConfigurationConfigure data field size for frame transmission. Configures the number of data bytes belonging to a Tx Buffer element. Data field sizes > 8 bytes are intended for CAN FD operation only.
  [2:0] TBDS — Tx Buffer Data Field Size 3'b000 = 8 byte data field 3'b001 = 12 byte data field 3'b010 = 16 byte data field 3'b011 = 20 byte data field 3'b100 = 24 byte data field 3'b101 = 32 byte data field 3'b110 = 48 byte data field 3'b111 = 64 byte data field Note: In case the data length code DLC of a Tx Buffer element is configured to a value higher than the Tx Buffer data field size MCAN_TXESC[2-0] TBDS, the bytes not defined by the Tx Buffer are transmitted as CCh (padding bytes).
0x2CC CFG_TXBRP ro — Tx Buffer Request Pending register. PendingTx buffers with pending transmission request. Each Tx Buffer has its own Transmission Request Pending bit. The bits are set via the MCAN_TXBAR register. The bits are reset after a requested transmission has completed or has been cancelled via the MCAN_TXBCR register. The MCAN_TXBRP bits are set only for those Tx Buffers configured via the MCAN_TXBC register. After a MCAN_TXBRP bit has been set, a Tx scan (see Tx Handling) is started to check for the pending Tx request with the highest priority (Tx Buffer with lowest Message ID).
  [31:0] TRP — Transmission Request Pending
0x2D0 CFG_TXBAR access not given — Tx Buffer Add Request register. Add transmission requests. Each Tx Buffer has its own Add Request bit. Writing 1h will set the corresponding Add Request bit; writing a 0h has no impact. This enables the Host CPU to set transmission requests for multiple Tx Buffers with one write to the MCAN_TXBAR register. The MCAN_TXBAR bits are set only for those Tx Buffers configured via the MCAN_TXBC register. When no Tx scan is running, the bits are reset immediately, else the bits remain set until the Tx scan process has completed. Note: If an add request is applied for a Tx Buffer with pending transmission request (corresponding MCAN_TXBRP bit already set), this add request is ignored.
  [31:0] AR — Add request (access R/W0TC)
0x2D4 CFG_TXBCR access not given — Tx Buffer Cancellation Request register. Request cancellation of pending transmissions. Each Tx Buffer has its own Cancellation Request bit. Writing a 1h will set the corresponding Cancellation Request bit; writing a 0h has no impact. This enables the Host CPU to set cancellation requests for multiple Tx Buffers with one write to the MCAN_TXBCR register. The MCAN_TXBCR bits are set only for those Tx Buffers configured via the MCAN_TXBC register. The bits remain set until the corresponding bit of the MCAN_TXBRP register is reset.
  [31:0] CR — Cancellation Request (access R/W0TC)
0x2D8 CFG_TXBTO ro — Tx Buffer Transmission Occurred register. Signals successful transmissions, set when corresponding MCAN_TXBRP flag is cleared. Each Tx Buffer has its own Transmission Occurred bit. The bits are set when the corresponding MCAN_TXBRP bit is cleared after a successful transmission. The bits are reset when a new transmission is requested by writing a 1h to the corresponding bit of register the MCAN_TXBAR register.
  [31:0] TO — Transmission Occurred
0x2DC CFG_TXBCF ro — Tx Buffer Cancellation Finished register. Signals successful transmit cancellation, set when corresponding MCAN_TXBRP flag is cleared after cancellation request. Each Tx Buffer has its own Cancellation Finished bit. The bits are set when the corresponding MCAN_TXBRP bit is cleared after a cancellation was requested via the MCAN_TXBCR register. In case the corresponding MCAN_TXBRP bit was not set at the point of cancellation, MCAN_TXBCF[n] CF bit is set immediately. The bits are reset when a new transmission is requested by writing a 1h to the corresponding bit of the MCAN_TXBAR register.
  [31:0] CF — Cancellation Finished
0x2E0 CFG_TXBTIE — Tx Buffer Transmission Interrupt Enable register. Enable transmit interrupts for selected Tx buffers.
  [31:0] TIE — Transmission Interrupt Enable
0x2E4 CFG_TXBCIE — Tx Buffer Cancellation Finished Interrupt Enable register. Enable cancellation finished interrupts for selected Tx buffers.
  [31:0] CFIE — Cancellation Finished Interrupt Enable
0x2F0 CFG_TXEFC — Tx Event FIFO Configuration register. Tx event FIFO watermark, size and start address.
  [29:24] EFWM — Event FIFO Watermark 6'h00 = Watermark interrupt disabled 6'h01-6'h20 (1-32) = Level for Tx Event FIFO watermark interrupt (MCAN_IR[13] TEFW) > 6'h20 (32) = Watermark interrupt disabled
  [21:16] EFS — Event FIFO Size 6'h00 = Tx Event FIFO disabled 6'h01-6'h20 (1-32) = Number of Tx Event FIFO elements > 6'h20 (32) = Values greater than 32 are interpreted as 32 The Tx Event FIFO elements are indexed from 0 to MCAN_TXEFC[21-16] EFS field - 1.
  [15:2] EFSA — Event FIFO Start Address Start address of Tx Event FIFO in Message RAM (32-bit word address, see Message RAM Configuration).
0x2F4 CFG_TXEFS ro — Tx Event FIFO Status register. Tx event FIFO element lost/full indication, put index, get index, and fill level.
  [25] TEFL — Tx Event FIFO Element Lost This bit is a copy of interrupt flag MCAN_IR[15] TEFL. When the MCAN_IR[15] TEFL flag is reset, this bit is also reset. 1'b0 = No Tx Event FIFO element lost 1'b1 = Tx Event FIFO element lost, also set after write attempt to Tx Event FIFO of size zero.
  [24] EFF — Event FIFO Full
  [20:16] EFPI — Event FIFO Put Index
  [12:8] EFGI — Event FIFO Get Index
  [5:0] EFFL — Event FIFO FIll Level
0x2F8 CFG_TXEFA ro — Tx Event FIFO Acknowledge register. Tx event FIFO acknowledge last index of read elements, updates get index and fill level.
  [4:0] EFAI — Event FIFO Acknowledge Index After the Host CPU has read an element or a sequence of elements from the Tx Event FIFO it has to write the index of the last element read from Tx Event FIFO to the MCAN_TXEFA[4-0] EFAI field. This will set the Tx Event FIFO Get Index MCAN_TXEFS[12-8] EFGI field to the MCAN_TXEFA[4-0] EFAI field + 1 and update the Event FIFO Fill Level MCAN_TXEFS[5-0] EFFL field.
